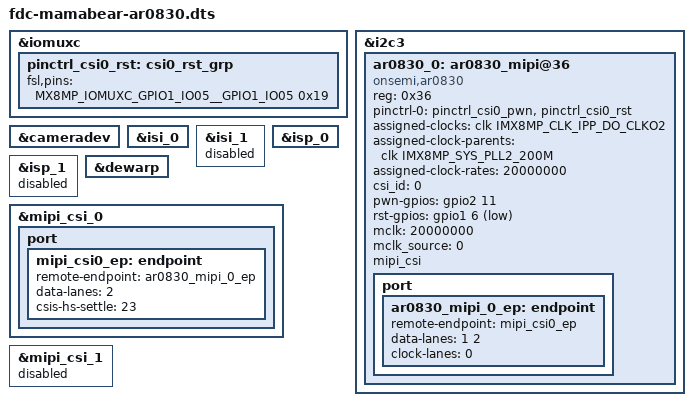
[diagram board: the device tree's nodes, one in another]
// SPDX-License-Identifier: (GPL-2.0+ OR MIT)
/*
 * Copyright 2019-2024 Future Electronics
*/

/dts-v1/;


#include "fdc-mamabear.dts"

/ {
	/delete-node/mipi_cam_reset;
};

&iomuxc {

	pinctrl_csi0_rst: csi0_rst_grp {
		fsl,pins = <
			MX8MP_IOMUXC_GPIO1_IO05__GPIO1_IO05	0x19
		>;
	};
};

&i2c3 {
	/delete-node/ap1302_mipi@3c;

	ar0830_0: ar0830_mipi@36 {
		compatible = "onsemi,ar0830";
		reg = <0x36>;
		pinctrl-names = "default";
//		pinctrl-0 = <&pinctrl_csi0_pwn>, <&pinctrl_csi0_rst>, <&pinctrl_csi_mclk>;
		pinctrl-0 = <&pinctrl_csi0_pwn>, <&pinctrl_csi0_rst>;
//		clocks = <&clk IMX8MP_CLK_IPP_DO_CLKO2>;
		clock-names = "csi_mclk";
		assigned-clocks = <&clk IMX8MP_CLK_IPP_DO_CLKO2>;
		assigned-clock-parents = <&clk IMX8MP_SYS_PLL2_200M>;
		assigned-clock-rates = <20000000>;
		csi_id = <0>;
		pwn-gpios = <&gpio2 11 GPIO_ACTIVE_HIGH>;
		rst-gpios = <&gpio1 6 GPIO_ACTIVE_LOW>;
		mclk = <20000000>;
		mclk_source = <0>;
		mipi_csi;
		status = "okay";

		port {
			ar0830_mipi_0_ep: endpoint {
				remote-endpoint = <&mipi_csi0_ep>;
				data-lanes = <1 2>;
				clock-lanes = <0>;
			};
		};
	};
};

&cameradev {
	status = "okay";
};
&isi_0 {
	status = "okay";
};

&isi_1 {
	status = "disabled";
};

&isp_0 {
	status = "okay";
};

&isp_1 {
	status = "disabled";
};

&dewarp {
	status = "okay";
};

&mipi_csi_0 {
	status = "okay";
	//clock-frequency = <266000000>;
	//assigned-clock-parents = <&clk IMX8MP_SYS_PLL1_266M>;
	//assigned-clock-rates = <266000000>;

	port {
		mipi_csi0_ep: endpoint {
			remote-endpoint = <&ar0830_mipi_0_ep>;
			data-lanes = <2>;
			csis-hs-settle = <23>;
		};
	};
};

&mipi_csi_1 {
	status = "disabled";
};
